# STM32N657xx register map
File version: 1.0
Registers are 32-bit, read-write, reset 0x0 unless marked. A register's access mark holds for its fields unless they carry their own. Offsets are from the block's base; [hi:lo] are bit positions; {n}, {i} and the like mark numbered series.

## RNG
Base 0x44020000
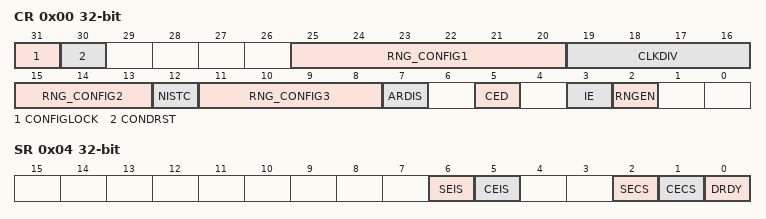
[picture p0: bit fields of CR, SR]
0x00 CR — RNG control register
  [31] CONFIGLOCK
  [30] CONDRST
  [25:20] RNG_CONFIG1
  [19:16] CLKDIV
    0=BY_1 (No clock division); 1=BY_2 (2 RNG clock cycles per internal RNG clock); 2=BY_4 (4 RNG clock cycles per internal RNG clock); 3=BY_8 (8 RNG clock cycles per internal RNG clock); 4=BY_16 (16 RNG clock cycles per internal RNG clock); 5=BY_32 (32 RNG clock cycles per internal RNG clock); 6=BY_64 (64 RNG clock cycles per internal RNG clock); 7=BY_128 (128 RNG clock cycles per internal RNG clock); 8=BY_256 (256 RNG clock cycles per internal RNG clock); 9=BY_512 (512 RNG clock cycles per internal RNG clock); 10=BY_1024 (1024 RNG clock cycles per internal RNG clock); 11=BY_2048 (2048 RNG clock cycles per internal RNG clock); 12=BY_4096 (4096 RNG clock cycles per internal RNG clock); 13=BY_8192 (8192 RNG clock cycles per internal RNG clock); 14=BY_16384 (16384 RNG clock cycles per internal RNG clock); 15=BY_32768 (32768 RNG clock cycles per internal RNG clock)
  [15:13] RNG_CONFIG2
  [12] NISTC
  [11:8] RNG_CONFIG3
  [7] ARDIS
  [5] CED
  [3] IE
  [2] RNGEN
0x04 SR — RNG status register
  [6] SEIS, [5] CEIS, [2] SECS, [1] CECS, [0] DRDY
0x08 DR — RNG data register
0x10 HTCR — RNG health test configuration register
  [31:0] HTCFG

## HASH
Base 0x44020400
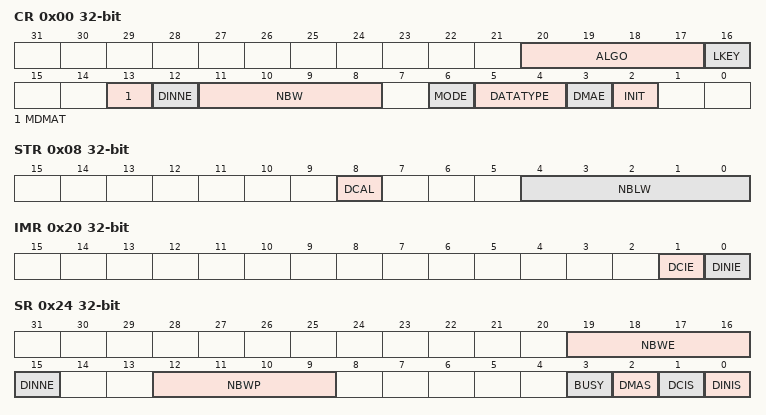
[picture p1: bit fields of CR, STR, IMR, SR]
0x00 CR — HASH control register
  [20:17] ALGO, [16] LKEY, [13] MDMAT, [12] DINNE, [11:8] NBW, [6] MODE, [5:4] DATATYPE, [3] DMAE, [2] INIT
0x04 DIN — HASH data input register
0x08 STR — HASH start register
  [8] DCAL, [4:0] NBLW
{0xC+4i} HR{i} (i=0..4) — HASH digest registers
0x20 IMR — HASH interrupt enable register
  [1] DCIE, [0] DINIE
0x24 SR — HASH status register
  [19:16] NBWE, [15] DINNE, [12:9] NBWP, [3] BUSY, [2] DMAS, [1] DCIS, [0] DINIS
{0xF8+4i} CSR[{i}] (i=0..102)
{0x310+4i} DIGEST_HR{i} (i=0..15) — HASH digest registers

## CRYP — Cryp Processor
Base 0x44020800
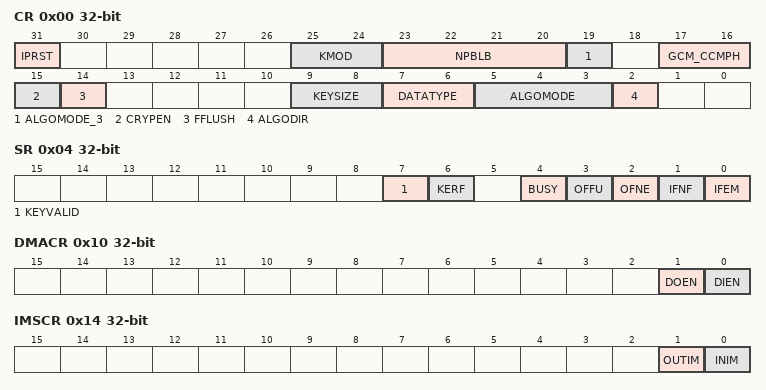
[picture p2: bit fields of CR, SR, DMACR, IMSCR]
0x00 CR — CRYP control register
  [31] IPRST — CRYP peripheral software reset
  [25:24] KMOD — Key mode selection
  [23:20] NPBLB — Number of Padding Bytes in Last Block of payload
  [19] ALGOMODE_3 — Algorithm mode
  [17:16] GCM_CCMPH — GCM or CCM Phase selection
  [15] CRYPEN — CRYP processor enable
  [14] FFLUSH — CRYP FIFO Flush
  [9:8] KEYSIZE — Key Size selection
  [7:6] DATATYPE — Data Type selection
  [5:3] ALGOMODE — Algorithm mode
  [2] ALGODIR — Algorithm direction (Encrypt/Decrypt)
0x04 SR — CRYP status register
  [7] KEYVALID — Key valid flag
  [6] KERF — Key error flag
  [4] BUSY — Busy bit
  [3] OFFU — Output FIFO full flag
  [2] OFNE — Output FIFO not empty flag
  [1] IFNF — Input FIFO not full flag
  [0] IFEM — Input FIFO empty flag
0x08 DIN — CRYP data input register
  [31:0] DATAIN — CRYP Data Input
0x0C DOUT — CRYP data output register
  [31:0] DATAOUT — CRYP Data Output
0x10 DMACR — CRYP DMA control register
  [1] DOEN — DMA Output Enable
  [0] DIEN — DMA Input Enable
0x14 IMSCR — CRYP interrupt mask set/clear register
  [1] OUTIM — Output FIFO service interrupt mask
  [0] INIM — Input FIFO service interrupt mask
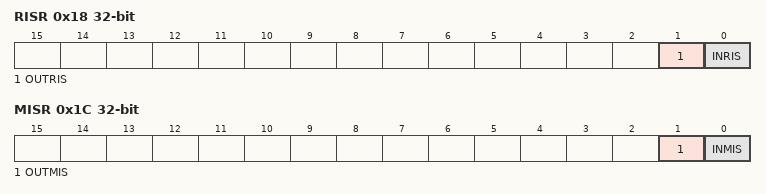
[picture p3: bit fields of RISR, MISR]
0x18 RISR — CRYP raw interrupt status register
  [1] OUTRIS — Output FIFO service raw interrupt mask
  [0] INRIS — Input FIFO service raw interrupt status
0x1C MISR — CRYP masked interrupt status register
  [1] OUTMIS — Output FIFO service masked interrupt status
  [0] INMIS — Input FIFO service masked interrupt status
0x20 K0LR — CRYP key left register 0
  [31:0] K — AES key bit x (x= 224 to 255)
0x24 K0RR — CRYP key right register 0
  [31:0] K — AES key bit x (x= 192 to 223)
0x28 K1LR — CRYP key left register 1
0x2C K1RR — CRYP key right register 1
0x30 K2LR — CRYP key left register 2
  [31:0] K — AES key bit x (x= 96 to 127)
0x34 K2RR — CRYP key right register 2
  [31:0] K — AES key bit x (x= 64 to 95)
0x38 K3LR — CRYP key left register 3
  [31:0] K — AES key bit x (x= 32 to 63)
0x3C K3RR — CRYP key right register 3
  [31:0] K — AES key bit x (x= 0 to 31)
0x40 IV0LR — CRYP initialization vector left-word register 0
  [31:0] IV — Initialization vector bit x (x= 0 to 31)
0x44 IV0RR — CRYP initialization vector right-word register 0
  [31:0] IV — Initialization vector bit x (x= 32 to 63)
0x48 IV1LR — CRYP initialization vector left-word register 1
  [31:0] K — AES key bit x (x= 160 to 291)
0x4C IV1RR — CRYP initialization vector right-word register 1
  [31:0] K — AES key bit x (x= 128 to 159)
{0x50+4i} CSGCMCCM{i}R (i=0..7) — CRYP GCM/GMAC or CCM/CMAC context swap register {i}
  [31:0] CSGCMCCM{i} — CRYP internal state registers for GCM, GMAC and CCM modes
{0x70+4i} CSGCM{i}R (i=0..7) — CRYP GCM/GMAC context swap register {i}
  [31:0] CSGCM{i} — CRYP internal state registers for GCM and GMAC modes
